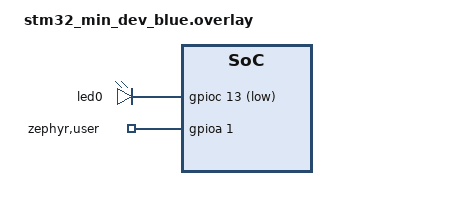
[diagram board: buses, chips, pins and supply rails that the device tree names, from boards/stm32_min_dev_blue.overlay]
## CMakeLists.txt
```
cmake_minimum_required(VERSION 3.22)

set(BOARD stm32_min_dev)

find_package(Zephyr REQUIRED HINTS $ENV{ZEPHYR_BASE})
project(horimetro)

FILE(GLOB app_sources src/*.c)
target_sources(app PRIVATE ${app_sources})

target_include_directories(app PRIVATE inc)
```

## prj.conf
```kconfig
# Comunicação

## UART
CONFIG_SERIAL=y # Receber dados do GPS e enviar pro GPRS
CONFIG_UART_ASYNC_API=n # Receber dados de forma assícrona usando Direct Memory Access (DMA)

## CAN
#TODO

# GPIO
CONFIG_GPIO=y # Ativar o controle dos pinos input e output

# Logging
CONFIG_LOG=y # Log de debug (UART 1)

CONFIG_LOG_DEFAULT_LEVEL=3
```

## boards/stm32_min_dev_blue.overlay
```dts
/ {
    // LED da BLuepill
    leds {
        compatible = "gpio-leds";
        led0: led {
            gpios = <&gpioc 13 GPIO_ACTIVE_LOW>;
        };
    };

    // Usado para inicializar aliases de outros devices no código
    aliases {
    };

    zephyr,user {
        gpios = <&gpioa 1 GPIO_ACTIVE_HIGH>; // Sensor de efeito HALL DO
    };
};
/* vim: set filetype=dts : */
```

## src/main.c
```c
#include <zephyr/kernel.h>
#include <zephyr/drivers/gpio.h>
#include <horimetro.h>

const struct gpio_dt_spec *const led = &(const struct gpio_dt_spec)GPIO_DT_SPEC_GET(DT_NODELABEL(led0), gpios);

int main(){
  horimetro_init();
  while (true) {
    k_sleep(K_USEC(100));
  }
}
```

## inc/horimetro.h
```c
#ifndef HORIMETRO_H
#define HORIMETRO_H

#include <zephyr/drivers/gpio.h>

/**
 * @file
 * @brief Biblioteca para a utilização do horímetro
 *
 * Este arquivo contém as definições e funções necessárias para inicialiazar 
 * e ler dados do horímetro desenvolvido pela equipe UNICAP Baja SAE
 *
 * @author Giancarlo Bonvenuto
 */

/**
 * @brief struct que contém todos os dados do horímetro
 *
 * Essa biblioteca não tem o propósito de possuir getters para
 * garantir que o código não tenha o overhead da função get().
 *
 * Então os valores devem ser acessados diretamente pelo struct, mas
 * não devem ser modificados!
 *
 */
extern struct horimetro_t {

  /**
   * @brief guarda o ciclo em que ocorreu o último pulso. **Não deve ser
   * alterado!**
   */
  uint32_t ultimoPulso;

  /**
   * @brief contém o RPM atual do motor
   */

  uint32_t rpm;
  /**
   * @brief contém o RPM mínimo que o motor consegue chegar e é definido no
   * `prj.conf`
   *
   * Esse campo auxilia as funções de calcular o RPM para saber se o motor está
   * parado ou ainda está girando.
   */

  uint32_t rpmMin; 
  /**
   * @brief um booleano que contém o estado do motor
   *
   * - `true`: o motor está ligado
   * - `false`: o motor está desligado
   */

  bool motorLigado;
  /**
   * @brief contém o device do sensor_hall e é definido na DeviceTree
   */

  const struct gpio_dt_spec *sensor_hall;
} horimetro;

/**
 * @brief essa função deve ser executada antes de qualquer acesso ao struct do
 * horímetro
 */
int horimetro_init();

#endif
```

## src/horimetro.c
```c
#include "horimetro.h"
#include "zephyr/drivers/gpio.h"
#include <stdlib.h>
#include <zephyr/kernel.h>
#include <zephyr/logging/log.h>
#include <zephyr/sys/time_units.h>
#include <zephyr/timing/timing.h>

struct horimetro_t horimetro;

// quantos milissegundos de gordurinha adicionamos ao timer
#define GordurinhaTIMER 100

LOG_MODULE_REGISTER(Horimetro);

// Vou destacar tudo que tem a ver com o timer para que caso não funcione seja
// mais fácil de remover
// === Coisas to timer ===
// Verifica periodicamente se o motor está ligado (Se essa função está sendo
// executada, é porque o timer expirou e o motor está desligado)
static struct k_timer my_timer;
static void motor_desligado(struct k_timer *timer_id) {
  horimetro.motorLigado = false;
  LOG_INF("Motor Desligado");
};

// === \Coisas to timer ===

// Callback quando o pino vira HIGH
// Pegamos o ciclo atual e a partir dele e do ultimoPulso conseguimos descobrir
// o rpm. Então guardamos esse ciclo como o últimoPulso e definimos o motor como
// ligado e reiniciamos o timer que definiria o motor como desligado
static void hall_callback(const struct device *dev, struct gpio_callback *cb,
                          uint32_t pins) {
  uint32_t cycle = k_cycle_get_32();
  horimetro.rpm =
      60000 / k_cyc_to_ms_near32(abs(horimetro.ultimoPulso - cycle));
  horimetro.ultimoPulso = cycle;
  LOG_INF("RPM: %u", horimetro.rpm);

  // Resetamos o timer que verifica se o motor está ligado
  // não precisamos veriricar se o motor está ligado se acabamos de receber
  // sinal dele
  horimetro.motorLigado = true;
  k_timer_start(&my_timer,
                K_MSEC((60000 / horimetro.rpmMin) + GordurinhaTIMER),
                K_NO_WAIT);
}

int horimetro_init() {
  LOG_INF("Inicializando...");
  horimetro.ultimoPulso = -1; // Ciclo do último pulso
  horimetro.rpm = 0;
  horimetro.rpmMin = 1500; // E máximo por volta de 4200
                             // Talvez possamos configurar isso aqui na
                             // Device tree? 🤔
  horimetro.sensor_hall =
      &(const struct gpio_dt_spec)GPIO_DT_SPEC_GET(DT_PATH(zephyr_user), gpios);
  horimetro.motorLigado = false;

  LOG_DBG("Valores do Horímetro definidos");

  if (!gpio_is_ready_dt(horimetro.sensor_hall)) {
    LOG_ERR("A porta %s não está pronta\n", horimetro.sensor_hall->port->name);
    return 0;
  }
  LOG_DBG("gpio ready");

  int err;

  err = gpio_pin_configure_dt(horimetro.sensor_hall, GPIO_INPUT);
  if (err < 0) {
    LOG_ERR("Não foi possível configurar o pino do sensor (%d)", err);
    return err;
  }

  LOG_DBG("gpio pin configure");

  err =
      gpio_pin_interrupt_configure_dt(horimetro.sensor_hall, GPIO_INT_EDGE_TO_ACTIVE);

  if (err < 0) {
    LOG_ERR("Não foi possível configurar o pino %s %d (Erro %d)",
            horimetro.sensor_hall->port->name, horimetro.sensor_hall->pin, err);
    return err;
  }
  LOG_DBG("gpio pin interrupt configure");

  static struct gpio_callback hall_cb_data;
  gpio_init_callback(&hall_cb_data, hall_callback, BIT(horimetro.sensor_hall->pin));
  LOG_DBG("gpio init callback");
  gpio_add_callback_dt(horimetro.sensor_hall, &hall_cb_data);
  LOG_DBG("gpio add callback");

  // Inicia o timer que verifica se o motor está ligado
  // __Esse timer não se reinicia sozinho__
  k_timer_init(&my_timer, motor_desligado, NULL);
  k_timer_start(&my_timer,
                K_MSEC((60000 / horimetro.rpmMin) + GordurinhaTIMER),
                K_NO_WAIT);
  LOG_INF("Inicializado!");
  return 0;
}
```
